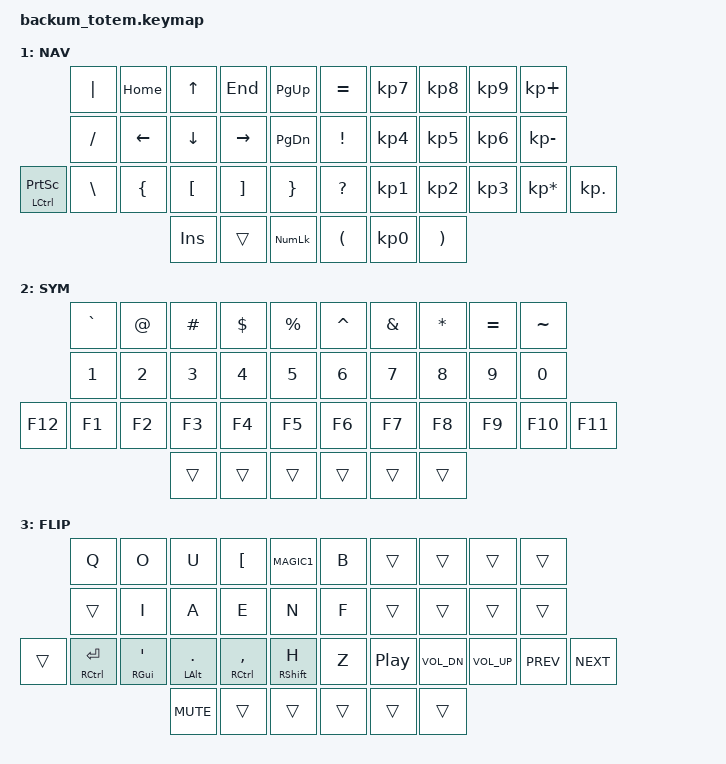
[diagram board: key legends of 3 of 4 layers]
//
//                                                        ▀▀▀▀▀     ▀▀▀▀▀          ▀▀█▀▀
//                                                        ▄▀▀▀▄  ▄  ▄▀▀▀▄  ▄  ▄▀▀▀▄  █  ▄▀▀▀▄
//                                                        █   █  █  █   █  █  █   █  █  █   █
//                                                         ▀▀▀   █   ▀▀▀   █   ▀▀▀   ▀   ▀▀▀
//                                                               █      ▄▄▄█▄▄▄    █   █  
//                                                               ▀      █  █  █     █▄█
//                                                             ▀▀▀▀▀    █  █  █      ▀
//                                                                      ▀  ▀  ▀
//
// ▄▄▄▄▄▄▄▄▄▄▄▄▄▄▄▄▄▄▄▄▄▄▄▄▄▄▄▄▄▄▄▄▄▄▄▄▄▄▄▄▄▄▄▄▄▄▄▄▄▄▄▄▄▄▄▄▄▄▄▄▄▄▄▄▄▄▄▄▄▄▄▄▄▄▄▄▄▄▄▄▄▄▄▄▄▄▄▄▄▄▄▄▄▄▄▄▄▄▄▄▄▄▄▄▄▄▄▄▄▄▄▄▄▄▄▄▄▄▄▄▄▄▄▄▄▄▄▄▄▄▄▄▄▄▄▄▄▄▄▄▄▄▄▄▄▄▄▄▄
       

#include <behaviors.dtsi>
#include <dt-bindings/zmk/keys.h>
#include <dt-bindings/zmk/bt.h>
#include <dt-bindings/zmk/outputs.h>

#define BASE 0
#define NAV  1
#define SYM  2
#define FLIP 3

&mt {
  quick-tap-ms = <180>;
  flavor = "hold-preferred";
  tapping-term-ms = <160>;
};

&lt {
  quick-tap-ms = <180>;
  flavor = "tap-preferred";
  tapping-term-ms = <160>;
};

/ {
    behaviors {
        lt_repeat: layer_tap_repeat {
            compatible = "zmk,behavior-hold-tap";
            #binding-cells = <2>;
            tapping-term-ms = <160>;
            quick-tap-ms = <180>;
            flavor = "tap-preferred";
            bindings = <&mo>, <&key_repeat>;
        };
		
		mt_repeat: mt_repeat {
			compatible = "zmk,behavior-hold-tap";
			#binding-cells = <2>;
			tapping-term-ms = <160>;
			flavor = "tap-preferred";
			bindings = <&kp>, <&key_repeat>;
		};

        mt_tap: mod_tap_tap_preferred {
            compatible = "zmk,behavior-hold-tap";
            #binding-cells = <2>;
            flavor = "tap-preferred";
            tapping-term-ms = <160>;
            quick-tap-ms = <180>;
            bindings = <&kp>, <&kp>;
        };
    };

     combos {
            compatible = "zmk,combos";
            combo_semi {
                timeout-ms = <50>;
                key-positions = <18 37>;
                bindings = <&kp SEMI>;
			};
			
			combo_colon {
                timeout-ms = <50>;
                key-positions = <19 37>;
                bindings = <&kp COLON>;
			};
			
			
			combo_enter {
				timeout-ms = <50>;
				key-positions = <10 11 12>;
				bindings = <&kp RET>;
			};

    };

    

        keymap {
                compatible = "zmk,keymap";
// ▄▄▄▄▄▄▄▄▄▄▄▄▄▄▄▄▄▄▄▄▄▄▄▄▄▄▄▄▄▄▄▄▄▄▄▄▄▄▄▄▄▄▄▄▄▄▄▄▄▄▄▄▄▄▄▄▄▄▄▄▄▄▄▄▄▄▄▄▄▄▄▄▄▄▄▄▄▄▄▄▄▄▄▄▄▄▄▄▄▄▄▄▄▄▄▄▄▄▄▄▄▄▄▄▄▄▄▄▄▄▄▄▄▄▄▄▄▄▄▄▄▄▄▄▄▄▄▄▄▄▄▄▄▄▄▄▄▄▄▄▄▄▄▄▄▄▄▄▄

                base_layer {
// ┏━━━━━━━━━━━━━━━━━━━━━━━━━━━━━━━━━━━━━━━┓
label= "BASE"                              ;
// ┗━━━━━━━━━━━━━━━━━━━━━━━━━━━━━━━━━━━━━━━┛
//             ┏━━━━━━━━━━━┳━━━━━━━━━━━┳━━━━━━━━━━━┳━━━━━━━━━━━┳━━━━━━━━━━━┓   ┏━━━━━━━━━━━┳━━━━━━━━━━━┳━━━━━━━━━━━┳━━━━━━━━━━━┳━━━━━━━━━━━┓
//             ┃     V    0┃     M    1┃     L    2┃     C    3┃     P    4┃   ┃     B    5┃    Mag1  6┃     U    7┃     O    8┃     Q    9┃
//             ┣━━━━━━━━━━━╋━━━━━━━━━━━╋━━━━━━━━━━━╋━━━━━━━━━━━╋━━━━━━━━━━━┫   ┣━━━━━━━━━━━╋━━━━━━━━━━━╋━━━━━━━━━━━╋━━━━━━━━━━━╋━━━━━━━━━━━┫
//             ┃     S   10┃     T   11┃     R   12┃     D   13┃     Y   14┃   ┃     F   15┃     N   16┃     E   17┃     A   18┃     I   19┃
// ┏━━━━━━━━━━━╋━━━━━━━━━━━╋━━━━━━━━━━━╋━━━━━━━━━━━╋━━━━━━━━━━━╋━━━━━━━━━━━┫   ┣━━━━━━━━━━━╋━━━━━━━━━━━╋━━━━━━━━━━━╋━━━━━━━━━━━╋━━━━━━━━━━━╋━━━━━━━━━━━┓
// ┃Ctrl/Tab 20┃     X   21┃     K   22┃     J   23┃     G   24┃     W   25┃   ┃     Z   26┃     H   27┃     ,   28┃     .   29┃     '   30┃Ctrl/Ret 31┃
// ┗━━━━━━━━━━━┻━━━━━━━━━━━┻━━━━━━━━━━━╋━━━━━━━━━━━╋━━━━━━━━━━━╋━━━━━━━━━━━┫   ┣━━━━━━━━━━━╋━━━━━━━━━━━╋━━━━━━━━━━━╋━━━━━━━━━━━┻━━━━━━━━━━━┻━━━━━━━━━━━┛
//                                     ┃ Sym/Esc 32┃   Space 33┃    Bspc 34┃   ┃Shift/BS 35┃  Gr/Rep 36┃Alt/Mag2 37┃
//                                     ┗━━━━━━━━━━━┻━━━━━━━━━━━┻━━━━━━━━━━━┛   ┗━━━━━━━━━━━┻━━━━━━━━━━━┻━━━━━━━━━━━┛
 bindings = <

                  &kp V                &kp M           &kp L           &kp C            &kp P               &kp B              [&kp *MAGIC1*]    &kp U              &kp O               &kp Q
                  &kp S                &kp T           &kp R           &kp D            &kp Y               &kp F              &kp N             &kp E              &kp A               &kp I
    &mt LCTL TAB  &mt_tap LGUI X       &mt_tap LALT K  &mt_tap LCTL J  &mt_tap LSHFT G  &kp W               &kp Z              &mt_tap RSHFT H   &mt_tap RCTL COMMA &mt_tap LALT DOT    &mt_tap RGUI SQT   &mt_tap RCTL RET
											           &lt SYM ESC     &lt NAV SPC      &lt FLIP BSPC       &mt RSHFT LC(BSPC) [&mt_repeat]      [&lt FLIP *MAGIC2*] 
                        >;
                };

// ▄▄▄▄▄▄▄▄▄▄▄▄▄▄▄▄▄▄▄▄▄▄▄▄▄▄▄▄▄▄▄▄▄▄▄▄▄▄▄▄▄▄▄▄▄▄▄▄▄▄▄▄▄▄▄▄▄▄▄▄▄▄▄▄▄▄▄▄▄▄▄▄▄▄▄▄▄▄▄▄▄▄▄▄▄▄▄▄▄▄▄▄▄▄▄▄▄▄▄▄▄▄▄▄▄▄▄▄▄▄▄▄▄▄▄▄▄▄▄▄▄▄▄▄▄▄▄▄▄▄▄▄▄▄▄▄▄▄▄▄▄▄▄▄▄▄▄▄▄

                nav_layer {
// ┏━━━━━━━━━━━━━━━━━━━━━━━━━━━━━━━━━━━━━━━┓
label= "NAV"                               ;
// ┗━━━━━━━━━━━━━━━━━━━━━━━━━━━━━━━━━━━━━━━┛
//             ┏━━━━━━━━━━━┳━━━━━━━━━━━┳━━━━━━━━━━━┳━━━━━━━━━━━┳━━━━━━━━━━━┓   ┏━━━━━━━━━━━┳━━━━━━━━━━━┳━━━━━━━━━━━┳━━━━━━━━━━━┳━━━━━━━━━━━┓
//             ┃     |     ┃    Home   ┃     UP    ┃    End    ┃    PgUp   ┃   ┃     =     ┃     7     ┃     8     ┃     9     ┃     +     ┃
//             ┣━━━━━━━━━━━╋━━━━━━━━━━━╋━━━━━━━━━━━╋━━━━━━━━━━━╋━━━━━━━━━━━┫   ┣━━━━━━━━━━━╋━━━━━━━━━━━╋━━━━━━━━━━━╋━━━━━━━━━━━╋━━━━━━━━━━━┫
//             ┃     /     ┃    LEFT   ┃    DOWN   ┃   RIGHT   ┃    PgDn   ┃   ┃     <     ┃     4     ┃     5     ┃     6     ┃     -     ┃
// ┏━━━━━━━━━━━╋━━━━━━━━━━━╋━━━━━━━━━━━╋━━━━━━━━━━━╋━━━━━━━━━━━╋━━━━━━━━━━━┫   ┣━━━━━━━━━━━╋━━━━━━━━━━━╋━━━━━━━━━━━╋━━━━━━━━━━━╋━━━━━━━━━━━╋━━━━━━━━━━━┓
// ┃ Ctrl/Prnt ┃     \     ┃     {     ┃     [     ┃     ]     ┃     }     ┃   ┃     >     ┃     1     ┃     2     ┃     3     ┃     *     ┃     .     ┃
// ┗━━━━━━━━━━━┻━━━━━━━━━━━┻━━━━━━━━━━━╋━━━━━━━━━━━╋━━━━━━━━━━━╋━━━━━━━━━━━┫   ┣━━━━━━━━━━━╋━━━━━━━━━━━╋━━━━━━━━━━━╋━━━━━━━━━━━┻━━━━━━━━━━━┻━━━━━━━━━━━┛
//                                     ┃   Insert  ┃           ┃  Num Lock ┃   ┃     (     ┃     0     ┃     )     ┃
//                                     ┗━━━━━━━━━━━┻━━━━━━━━━━━┻━━━━━━━━━━━┛   ┗━━━━━━━━━━━┻━━━━━━━━━━━┻━━━━━━━━━━━┛
 bindings = <

                     &kp PIPE    &kp HOME    &kp UP      &kp END     &kp PG_UP       &kp EQUAL   &kp KP_N7   &kp KP_N8   &kp KP_N9   &kp KP_PLUS
                     &kp FSLH    &kp LEFT    &kp DOWN    &kp RIGHT   &kp PG_DN       &kp EXCL    &kp KP_N4   &kp KP_N5   &kp KP_N6   &kp KP_MINUS
    &mt LCTL PSCRN   &kp BSLH    &kp LBRC    &kp LBKT    &kp RBKT    &kp RBRC        &kp QMARK   &kp KP_N1   &kp KP_N2   &kp KP_N3   &kp KP_MULTIPLY &kp KP_DOT      
                                             &kp INS     &trans      &kp KP_NUM      &kp LPAR    &kp KP_N0   &kp RPAR       
                        >;
                };

// ▄▄▄▄▄▄▄▄▄▄▄▄▄▄▄▄▄▄▄▄▄▄▄▄▄▄▄▄▄▄▄▄▄▄▄▄▄▄▄▄▄▄▄▄▄▄▄▄▄▄▄▄▄▄▄▄▄▄▄▄▄▄▄▄▄▄▄▄▄▄▄▄▄▄▄▄▄▄▄▄▄▄▄▄▄▄▄▄▄▄▄▄▄▄▄▄▄▄▄▄▄▄▄▄▄▄▄▄▄▄▄▄▄▄▄▄▄▄▄▄▄▄▄▄▄▄▄▄▄▄▄▄▄▄▄▄▄▄▄▄▄▄▄▄▄▄▄▄▄


                sym_layer {
// ┏━━━━━━━━━━━━━━━━━━━━━━━━━━━━━━━━━━━━━━━┓
label= "SYM"                               ;
// ┗━━━━━━━━━━━━━━━━━━━━━━━━━━━━━━━━━━━━━━━┛
//             ┏━━━━━━━━━━━┳━━━━━━━━━━━┳━━━━━━━━━━━┳━━━━━━━━━━━┳━━━━━━━━━━━┓   ┏━━━━━━━━━━━┳━━━━━━━━━━━┳━━━━━━━━━━━┳━━━━━━━━━━━┳━━━━━━━━━━━┓
//             ┃     `     ┃     @     ┃     #     ┃     $     ┃     %     ┃   ┃     ˆ     ┃     &     ┃     *     ┃     =     ┃     ~     ┃
//             ┣━━━━━━━━━━━╋━━━━━━━━━━━╋━━━━━━━━━━━╋━━━━━━━━━━━╋━━━━━━━━━━━┫   ┣━━━━━━━━━━━╋━━━━━━━━━━━╋━━━━━━━━━━━╋━━━━━━━━━━━╋━━━━━━━━━━━┫
//             ┃     1     ┃     2     ┃     3     ┃     4	   ┃     5     ┃   ┃     6     ┃     7     ┃     8     ┃     9     ┃     0     ┃
// ┏━━━━━━━━━━━╋━━━━━━━━━━━╋━━━━━━━━━━━╋━━━━━━━━━━━╋━━━━━━━━━━━╋━━━━━━━━━━━┫   ┣━━━━━━━━━━━╋━━━━━━━━━━━╋━━━━━━━━━━━╋━━━━━━━━━━━╋━━━━━━━━━━━╋━━━━━━━━━━━┓
// ┃    F12    ┃     F1    ┃     F2    ┃     F3    ┃     F4    ┃     F5    ┃   ┃     F6    ┃     F7    ┃     F8    ┃     F9    ┃    F10    ┃    F11    ┃
// ┗━━━━━━━━━━━┻━━━━━━━━━━━┻━━━━━━━━━━━╋━━━━━━━━━━━╋━━━━━━━━━━━╋━━━━━━━━━━━┫   ┣━━━━━━━━━━━╋━━━━━━━━━━━╋━━━━━━━━━━━╋━━━━━━━━━━━┻━━━━━━━━━━━┻━━━━━━━━━━━┛
//                                     ┃           ┃           ┃           ┃   ┃           ┃           ┃           ┃
//                                     ┗━━━━━━━━━━━┻━━━━━━━━━━━┻━━━━━━━━━━━┛   ┗━━━━━━━━━━━┻━━━━━━━━━━━┻━━━━━━━━━━━┛
 bindings = <

                &kp GRAVE   &kp AT      &kp HASH    &kp DLLR    &kp PRCNT       &kp CARET   &kp AMPS    &kp STAR    &kp EQUAL   &kp TILDE       
                &kp N1      &kp N2      &kp N3      &kp N4      &kp N5          &kp N6      &kp N7      &kp N8      &kp N9      &kp N0 
    &kp F12     &kp F1      &kp F2      &kp F3      &kp F4      &kp F5          &kp F6      &kp F7      &kp F8      &kp F9      &kp F10     &kp F11         
                                        &trans      &trans      &trans          &trans      &trans      &trans      
                        >;
                };

// ▄▄▄▄▄▄▄▄▄▄▄▄▄▄▄▄▄▄▄▄▄▄▄▄▄▄▄▄▄▄▄▄▄▄▄▄▄▄▄▄▄▄▄▄▄▄▄▄▄▄▄▄▄▄▄▄▄▄▄▄▄▄▄▄▄▄▄▄▄▄▄▄▄▄▄▄▄▄▄▄▄▄▄▄▄▄▄▄▄▄▄▄▄▄▄▄▄▄▄▄▄▄▄▄▄▄▄▄▄▄▄▄▄▄▄▄▄▄▄▄▄▄▄▄▄▄▄▄▄▄▄▄▄▄▄▄▄▄▄▄▄▄▄▄▄▄▄▄▄


                flip_layer {
// ┏━━━━━━━━━━━━━━━━━━━━━━━━━━━━━━━━━━━━━━━┓
label= "FLIP"                              ;
// ┗━━━━━━━━━━━━━━━━━━━━━━━━━━━━━━━━━━━━━━━┛
//             ┏━━━━━━━━━━━┳━━━━━━━━━━━┳━━━━━━━━━━━┳━━━━━━━━━━━┳━━━━━━━━━━━┓   ┏━━━━━━━━━━━┳━━━━━━━━━━━┳━━━━━━━━━━━┳━━━━━━━━━━━┳━━━━━━━━━━━┓
//             ┃     Q     ┃     O     ┃     U     ┃    Mag1   ┃     B     ┃   ┃           ┃           ┃           ┃           ┃           ┃
//             ┣━━━━━━━━━━━╋━━━━━━━━━━━╋━━━━━━━━━━━╋━━━━━━━━━━━╋━━━━━━━━━━━┫   ┣━━━━━━━━━━━╋━━━━━━━━━━━╋━━━━━━━━━━━╋━━━━━━━━━━━╋━━━━━━━━━━━┫
//             ┃     I     ┃     A     ┃     E     ┃     N     ┃     F     ┃   ┃           ┃           ┃           ┃           ┃           ┃
// ┏━━━━━━━━━━━╋━━━━━━━━━━━╋━━━━━━━━━━━╋━━━━━━━━━━━╋━━━━━━━━━━━╋━━━━━━━━━━━┫   ┣━━━━━━━━━━━╋━━━━━━━━━━━╋━━━━━━━━━━━╋━━━━━━━━━━━╋━━━━━━━━━━━╋━━━━━━━━━━━┓
// ┃  Ctrl/Ret ┃     ,     ┃     -     ┃     .     ┃     P     ┃     K     ┃   ┃    Play   ┃    Vol-   ┃    Vol+   ┃    Prev   ┃    Next   ┃    Mute   ┃
// ┗━━━━━━━━━━━┻━━━━━━━━━━━┻━━━━━━━━━━━╋━━━━━━━━━━━╋━━━━━━━━━━━╋━━━━━━━━━━━┫   ┣━━━━━━━━━━━╋━━━━━━━━━━━╋━━━━━━━━━━━╋━━━━━━━━━━━┻━━━━━━━━━━━┻━━━━━━━━━━━┛
//                                     ┃           ┃           ┃           ┃   ┃           ┃           ┃           ┃
//                                     ┗━━━━━━━━━━━┻━━━━━━━━━━━┻━━━━━━━━━━━┛   ┗━━━━━━━━━━━┻━━━━━━━━━━━┻━━━━━━━━━━━┛
 bindings = <

                       &kp Q               &kp O               &kp U               &kp [*MAGIC1*]   &kp B           &trans         &trans        &trans        &trans      &trans
                       &kp I               &kp A               &kp E               &kp N            &kp F           &trans         &trans        &trans        &trans      &trans
    &mt_tap RCTL RET   &mt_tap RGUI SQT    &mt_tap LALT DOT    &mt_tap RCTL COMMA  &mt_tap RSHFT H  &kp Z           &kp C_PP       &kp C_VOL_DN  &kp C_VOL_UP  &kp C_PREV  &kp C_NEXT   &kp C_MUTE
											                   &trans              &trans           &trans          &trans         &trans 
                        >;
                };

// ▄▄▄▄▄▄▄▄▄▄▄▄▄▄▄▄▄▄▄▄▄▄▄▄▄▄▄▄▄▄▄▄▄▄▄▄▄▄▄▄▄▄▄▄▄▄▄▄▄▄▄▄▄▄▄▄▄▄▄▄▄▄▄▄▄▄▄▄▄▄▄▄▄▄▄▄▄▄▄▄▄▄▄▄▄▄▄▄▄▄▄▄▄▄▄▄▄▄▄▄▄▄▄▄▄▄▄▄▄▄▄▄▄▄▄▄▄▄▄▄▄▄▄▄▄▄▄▄▄▄▄▄▄▄▄▄▄▄▄▄▄▄▄▄▄▄▄▄▄



        };
};
